# STM32U585 register map
File version: 2.2
CPU: CM33 r0p1, little endian, MPU, FPU, 4 interrupt priority bits
Registers are 32-bit, read-write, reset 0x0 unless marked. A register's access mark holds for its fields unless they carry their own. Offsets are from the block's base; [hi:lo] are bit positions; {n}, {i} and the like mark numbered series.

## DCACHE
Base 0x40031400
Same registers: SEC_DCACHE 0x50031400
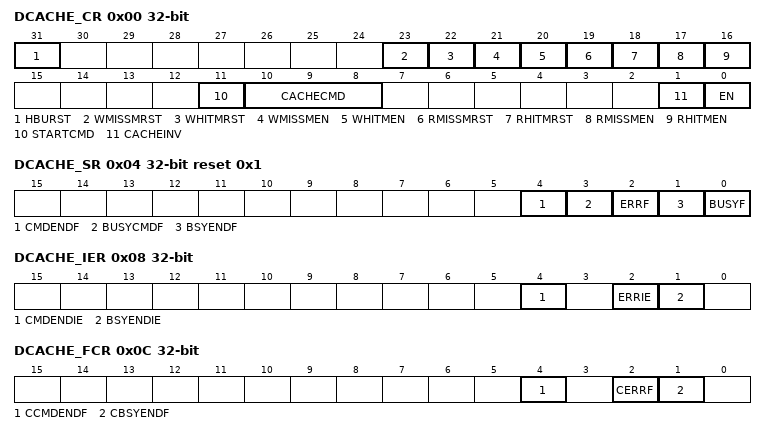
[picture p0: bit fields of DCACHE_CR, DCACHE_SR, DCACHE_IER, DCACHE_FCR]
0x00 DCACHE_CR access per field — DCACHE control register
  [31] HBURST rw, [23] WMISSMRST rw, [22] WHITMRST rw, [21] WMISSMEN rw, [20] WHITMEN rw, [19] RMISSMRST rw, [18] RHITMRST rw, [17] RMISSMEN rw, [16] RHITMEN rw, [11] STARTCMD wo, [10:8] CACHECMD rw, [1] CACHEINV wo, [0] EN rw
0x04 DCACHE_SR ro reset 0x1 — DCACHE status register
  [4] CMDENDF, [3] BUSYCMDF, [2] ERRF, [1] BSYENDF, [0] BUSYF
0x08 DCACHE_IER — DCACHE interrupt enable
  [4] CMDENDIE, [2] ERRIE, [1] BSYENDIE
0x0C DCACHE_FCR wo — DCACHE flag clear register
  [4] CCMDENDF, [2] CERRF, [1] CBSYENDF
0x10 DCACHE_RHMONR ro — DCACHE read-hit monitor register
  [31:0] RHITMON
0x14 DCACHE_RMMONR ro — DCACHE read-miss monitor register
  [15:0] MRISSMON — RMISSMON
0x20 DCACHE_WHMONR ro — write-hit monitor register
  [31:0] WHITMON
0x24 DCACHE_WMMONR ro — write-miss monitor register
  [15:0] WMISSMON
0x28 DCACHE_CMDRSADDRR — command range start address register
  [31:0] CMDSTARTADDR
0x2C DCACHE_CMDREADDRR — command range start address register
  [31:0] CMDENDADDR

## IWDG — Independent watchdog
Base 0x40003000
Same registers: SEC_IWDG 0x50003000
0x00 KR wo — Key register
  [15:0] KEY — Key value (write only, read
0x04 PR — Prescaler register
  [3:0] PR — Prescaler divider
0x08 RLR reset 0xFFF — Reload register
  [11:0] RL — Watchdog counter reload
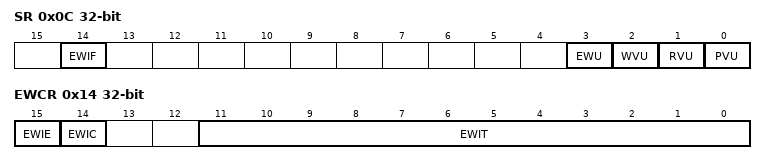
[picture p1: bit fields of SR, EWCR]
0x0C SR ro — Status register
  [14] EWIF — Watchdog Early interrupt flag
  [3] EWU — Watchdog interrupt comparator value update
  [2] WVU — Watchdog counter window value
  [1] RVU — Watchdog counter reload value
  [0] PVU — Watchdog prescaler value
0x10 WINR reset 0xFFF — Window register
  [11:0] WIN — Watchdog counter window
0x14 EWCR — IWDG early wakeup interrupt register
  [15] EWIE — Watchdog early interrupt enable
  [14] EWIC — Watchdog early interrupt acknowledge
  [11:0] EWIT — Watchdog counter window value

## GTZC1_MPCBB1
Base 0x40032C00
Same registers: SEC_GTZC1_MPCBB1 0x50032C00
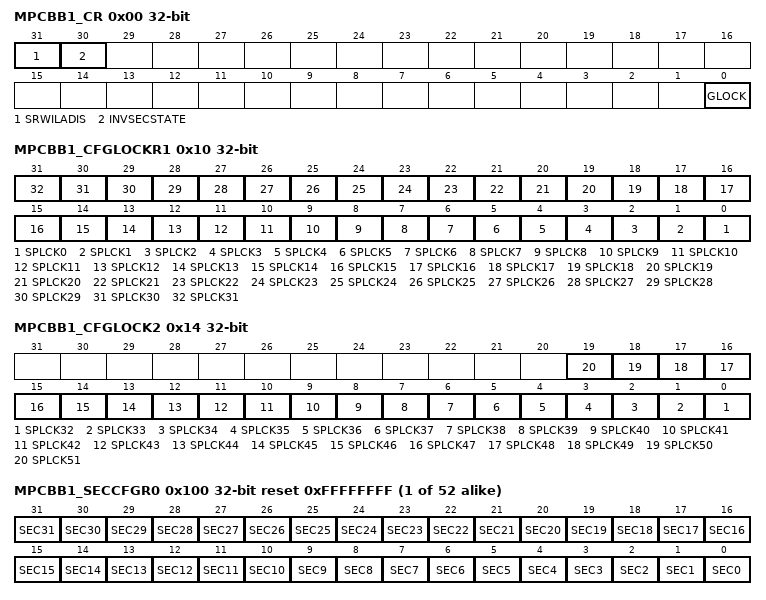
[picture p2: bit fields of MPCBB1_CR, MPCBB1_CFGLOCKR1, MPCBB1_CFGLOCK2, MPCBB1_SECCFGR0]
0x00 MPCBB1_CR — MPCBB control register
  [31] SRWILADIS — secure read/write illegal access disable
  [30] INVSECSTATE — SRAMx clocks security state
  [0] GLOCK — lock the control register of the MPCBB until next reset
0x10 MPCBB1_CFGLOCKR1 — GTZC1 SRAMz MPCBB configuration lock register 1
  [n] SPLCK{n} (n=0..31)
0x14 MPCBB1_CFGLOCK2 — GTZC1 SRAMz MPCBB configuration lock register 2
  [n-32] SPLCK{n} (n=32..51)
{0x100+4i} MPCBB1_SECCFGR{i} reset 0xFFFFFFFF (i=0..51) — MPCBBx security configuration for super-block x register
  [n] SEC{n} (n=0..31)
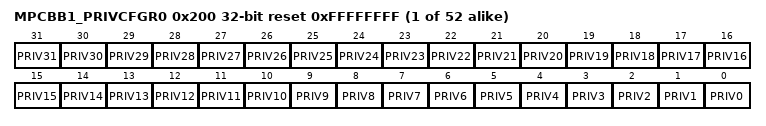
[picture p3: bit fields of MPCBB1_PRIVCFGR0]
{0x200+4i} MPCBB1_PRIVCFGR{i} reset 0xFFFFFFFF (i=0..51) — MPCBB privileged configuration for super-block x register
  [n] PRIV{n} (n=0..31)

## GTZC1_MPCBB2
Base 0x40033000
Same registers: SEC_GTZC1_MPCBB2 0x50033000
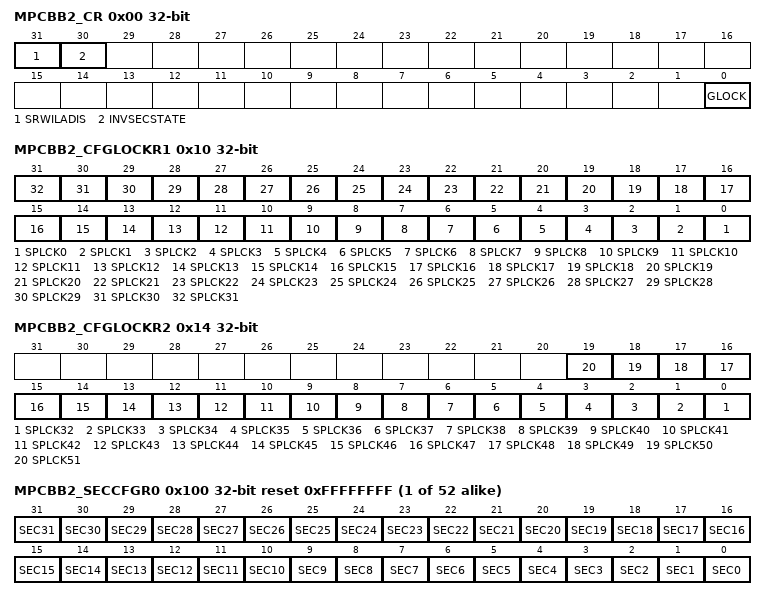
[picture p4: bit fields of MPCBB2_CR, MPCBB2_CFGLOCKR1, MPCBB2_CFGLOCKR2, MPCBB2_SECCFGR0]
0x00 MPCBB2_CR — MPCBB control register
  [31] SRWILADIS — secure read/write illegal access disable
  [30] INVSECSTATE — SRAMx clocks security state
  [0] GLOCK — lock the control register of the MPCBB until next reset
0x10 MPCBB2_CFGLOCKR1 — GTZC1 SRAMz MPCBB configuration lock register
  [n] SPLCK{n} (n=0..31)
0x14 MPCBB2_CFGLOCKR2 — GTZC1 SRAMz MPCBB configuration lock register 2
  [n-32] SPLCK{n} (n=32..51)
{0x100+4i} MPCBB2_SECCFGR{i} reset 0xFFFFFFFF (i=0..51) — MPCBBx security configuration for super-block x register
  [n] SEC{n} (n=0..31)
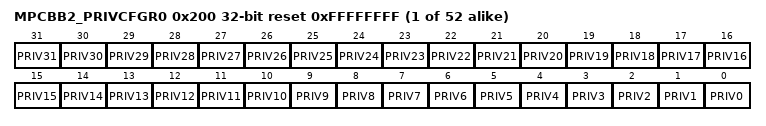
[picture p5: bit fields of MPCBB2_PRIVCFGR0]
{0x200+4i} MPCBB2_PRIVCFGR{i} reset 0xFFFFFFFF (i=0..51) — MPCBB privileged configuration for super-block x register
  [n] PRIV{n} (n=0..31)

## GTZC1_MPCBB3
Base 0x40033400
Same registers: SEC_GTZC1_MPCBB3 0x50033400
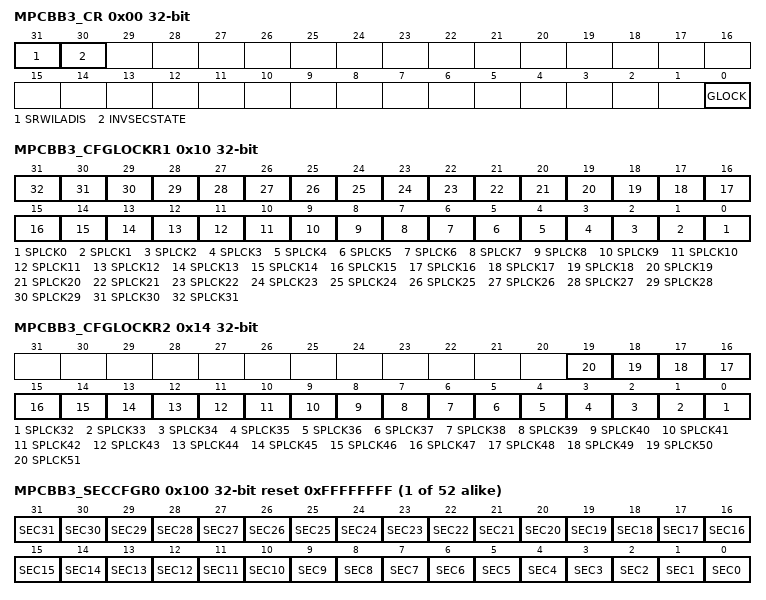
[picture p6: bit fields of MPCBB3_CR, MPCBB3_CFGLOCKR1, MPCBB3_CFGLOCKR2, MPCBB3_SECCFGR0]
0x00 MPCBB3_CR — MPCBB control register
  [31] SRWILADIS — secure read/write illegal access disable
  [30] INVSECSTATE — SRAMx clocks security state
  [0] GLOCK — lock the control register of the MPCBB until next reset
0x10 MPCBB3_CFGLOCKR1 — GTZC1 SRAMz MPCBB configuration lock register
  [n] SPLCK{n} (n=0..31)
0x14 MPCBB3_CFGLOCKR2 — GTZC3 SRAMz MPCBB configuration lock register 2
  [n-32] SPLCK{n} (n=32..51)
{0x100+4i} MPCBB3_SECCFGR{i} reset 0xFFFFFFFF (i=0..51) — MPCBBx security configuration for super-block x register
  [n] SEC{n} (n=0..31)
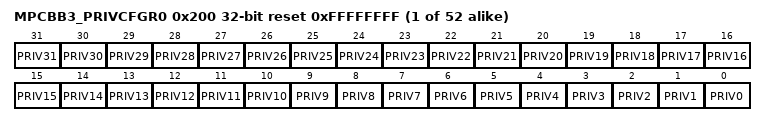
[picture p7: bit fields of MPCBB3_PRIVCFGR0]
{0x200+4i} MPCBB3_PRIVCFGR{i} reset 0xFFFFFFFF (i=0..51) — MPCBB privileged configuration for super-block x register
  [n] PRIV{n} (n=0..31)
